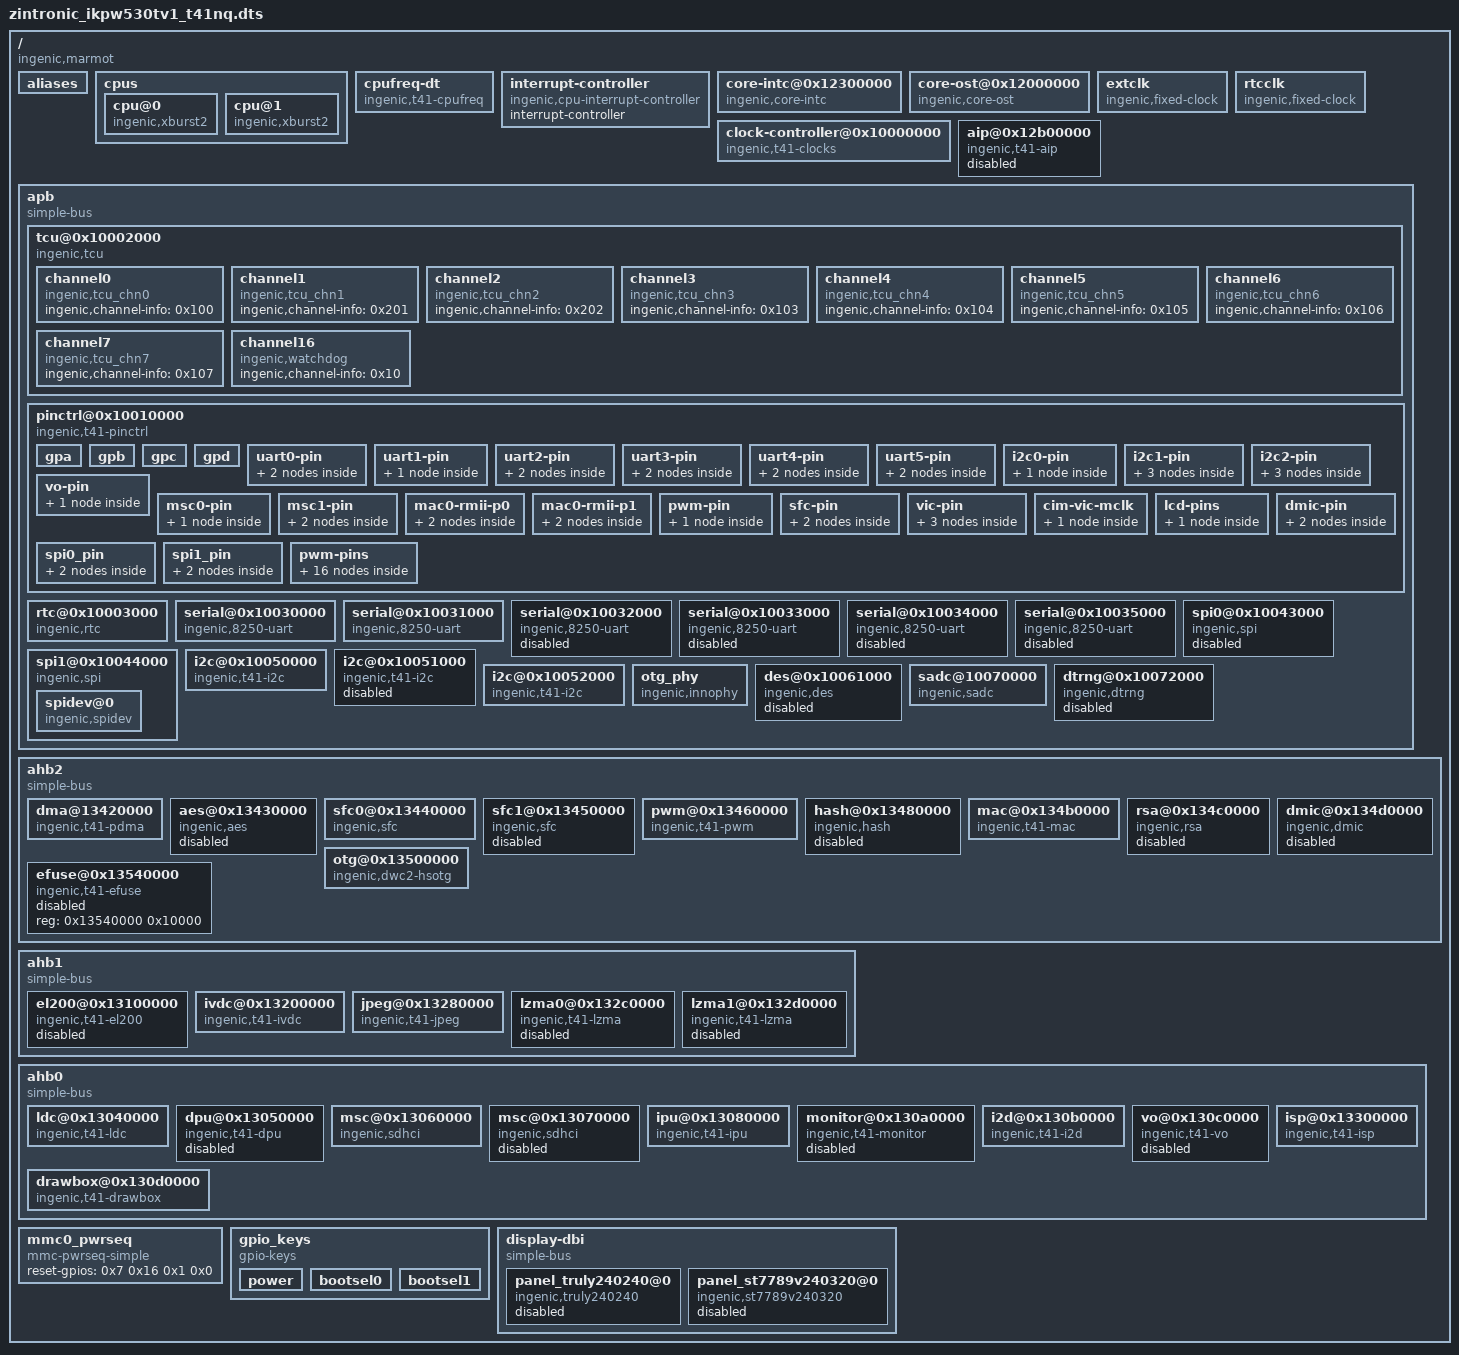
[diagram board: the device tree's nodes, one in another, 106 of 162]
/dts-v1/;
// version: 17
// last_comp_version: 16
// boot_cpuid_phys: 0x0

/ {
    #address-cells = <0x1>;
    #size-cells = <0x1>;
    compatible = "ingenic,marmot", "ingenic,t41";
    aliases {
        i2c0 = "/apb/i2c@0x10050000";
        i2c1 = "/apb/i2c@0x10051000";
        i2c2 = "/apb/i2c@0x10052000";
        vo = "/ahb0/vo@0x130c0000";
        uart0 = "/apb/serial@0x10030000";
        uart1 = "/apb/serial@0x10031000";
        uart2 = "/apb/serial@0x10032000";
        uart3 = "/apb/serial@0x10033000";
        uart4 = "/apb/serial@0x10034000";
        uart5 = "/apb/serial@0x10035000";
        msc0 = "/ahb0/msc@0x13060000";
        msc1 = "/ahb0/msc@0x13070000";
        mac0 = "/ahb2/mac@0x134b0000";
        spi0 = "/apb/spi0@0x10043000";
        spi1 = "/apb/spi1@0x10044000";
        sfc0 = "/ahb2/sfc0@0x13440000";
        sfc1 = "/ahb2/sfc1@0x13450000";
    };
    cpus {
        #address-cells = <0x1>;
        #size-cells = <0x0>;
        cpu@0 {
            device_type = "cpu";
            compatible = "ingenic,xburst2";
            reg = <0x0>;
            clock-frequency = <0x2FAF0800>;
        };
        cpu@1 {
            device_type = "cpu";
            compatible = "ingenic,xburst2";
            reg = <0x1>;
            clock-frequency = <0x2FAF0800>;
        };
    };
    cpufreq-dt {
        compatible = "ingenic,t41-cpufreq";
        status = "okay";
        operating-points = <0x124F80 0xDBBA0 0x10D880 0xDBBA0 0xF6180 0xDBBA0 0xDEA80 0xDBBA0 0xD9878 0xDBBA0 0xB71B0 0xDBBA0 0x927C0 0xDBBA0 0x7A120 0xDBBA0 0x61A80 0xDBBA0 0x5B8D8 0xDBBA0 0x493E0 0xDBBA0 0x30D40 0xDBBA0>;
    };
    interrupt-controller {
        #address-cells = <0x0>;
        #interrupt-cells = <0x1>;
        interrupt-controller;
        compatible = "ingenic,cpu-interrupt-controller";
        linux,phandle = <0x1>;
        phandle = <0x1>;
    };
    core-intc@0x12300000 {
        compatible = "ingenic,core-intc";
        reg = <0x12300000 0x1000>;
        interrupt-controller;
        #interrupt-cells = <0x1>;
        cpu-intc-map = <0x0 0x0 0x1 0x100 0x2 0x200 0x3 0x300>;
        interrupt-parent = <0x1>;
        interrupts = <0x2>;
        interrupt-names = "intc";
        linux,phandle = <0x4>;
        phandle = <0x4>;
    };
    core-ost@0x12000000 {
        compatible = "ingenic,core-ost";
        reg = <0x12000000 0x10000 0x12100000 0x10000>;
        interrupt-parent = <0x1>;
        interrupt-names = "sys_ost";
        interrupts = <0x4>;
        cpu-ost-map = <0x0 0x0 0x1 0x100>;
    };
    extclk {
        compatible = "ingenic,fixed-clock";
        clock-output-names = "ext";
        #clock-cells = <0x0>;
        clock-frequency = <0x16E3600>;
        linux,phandle = <0x2>;
        phandle = <0x2>;
    };
    rtcclk {
        compatible = "ingenic,fixed-clock";
        clock-output-names = "rtc_ext";
        #clock-cells = <0x0>;
        clock-frequency = <0x8000>;
        linux,phandle = <0x3>;
        phandle = <0x3>;
    };
    clock-controller@0x10000000 {
        compatible = "ingenic,t41-clocks";
        reg = <0x10000000 0x100>;
        clocks = <0x2 0x3>;
        clock-names = "ext", "rtc_ext";
        #clock-cells = <0x1>;
        little-endian;
    };
    aip@0x12b00000 {
        compatible = "ingenic,t41-aip";
        reg = <0x12B00000 0x10000>;
        interrupt-parent = <0x4>;
        interrupts = <0x28 0x27 0x26>;
        status = "disabled";
    };
    apb {
        compatible = "simple-bus";
        #address-cells = <0x1>;
        #size-cells = <0x1>;
        ranges;
        tcu@0x10002000 {
            compatible = "ingenic,tcu";
            reg = <0x10002000 0x200>;
            interrupt-parent = <0x4>;
            interrupt-names = "tcu_int0";
            interrupts = <0x1B>;
            interrupt-controller;
            status = "okay";
            channel0 {
                compatible = "ingenic,tcu_chn0";
                ingenic,channel-info = <0x100>;
            };
            channel1 {
                compatible = "ingenic,tcu_chn1";
                ingenic,channel-info = <0x201>;
            };
            channel2 {
                compatible = "ingenic,tcu_chn2";
                ingenic,channel-info = <0x202>;
            };
            channel3 {
                compatible = "ingenic,tcu_chn3";
                ingenic,channel-info = <0x103>;
            };
            channel4 {
                compatible = "ingenic,tcu_chn4";
                ingenic,channel-info = <0x104>;
            };
            channel5 {
                compatible = "ingenic,tcu_chn5";
                ingenic,channel-info = <0x105>;
            };
            channel6 {
                compatible = "ingenic,tcu_chn6";
                ingenic,channel-info = <0x106>;
            };
            channel7 {
                compatible = "ingenic,tcu_chn7";
                ingenic,channel-info = <0x107>;
            };
            channel16 {
                compatible = "ingenic,watchdog";
                ingenic,channel-info = <0x10>;
            };
        };
        pinctrl@0x10010000 {
            compatible = "ingenic,t41-pinctrl";
            reg = <0x10010000 0x1000>;
            ingenic,num-chips = <0x4>;
            ingenic,regs-offset = <0x100>;
            gpa {
                gpio-controller;
                #gpio-cells = <0x3>;
                #ingenic,pincfg-cells = <0x3>;
                #ingenic,pinmux-cells = <0x2>;
                interrupts = <0x11>;
                interrupt-parent = <0x4>;
                interrupt-controller;
                #interrupt-cells = <0x3>;
                ingenic,num-gpios = <0x20>;
                ingenic,pull-gpios-low = <0x55555555>;
                ingenic,pull-gpios-high = <0x55555555>;
                linux,phandle = <0x8>;
                phandle = <0x8>;
            };
            gpb {
                gpio-controller;
                #gpio-cells = <0x3>;
                #ingenic,pincfg-cells = <0x3>;
                #ingenic,pinmux-cells = <0x2>;
                interrupts = <0x10>;
                interrupt-parent = <0x4>;
                interrupt-controller;
                #interrupt-cells = <0x3>;
                ingenic,num-gpios = <0x20>;
                ingenic,pull-gpios-low = <0x55555555>;
                ingenic,pull-gpios-high = <0x55555555>;
                linux,phandle = <0x5>;
                phandle = <0x5>;
            };
            gpc {
                gpio-controller;
                #gpio-cells = <0x3>;
                #ingenic,pincfg-cells = <0x3>;
                #ingenic,pinmux-cells = <0x2>;
                interrupts = <0xF>;
                interrupt-parent = <0x4>;
                interrupt-controller;
                #interrupt-cells = <0x3>;
                ingenic,num-gpios = <0x20>;
                ingenic,pull-gpios-low = <0x55555555>;
                ingenic,pull-gpios-high = <0x55555555>;
                linux,phandle = <0x6>;
                phandle = <0x6>;
            };
            gpd {
                gpio-controller;
                #gpio-cells = <0x3>;
                #ingenic,pincfg-cells = <0x3>;
                #ingenic,pinmux-cells = <0x2>;
                interrupts = <0xE>;
                interrupt-parent = <0x4>;
                interrupt-controller;
                #interrupt-cells = <0x3>;
                ingenic,num-gpios = <0x20>;
                ingenic,pull-gpios-low = <0x55555555>;
                ingenic,pull-gpios-high = <0x55555555>;
                linux,phandle = <0x7>;
                phandle = <0x7>;
            };
            uart0-pin {
                uart0-pb {
                    ingenic,pinmux = <0x5 0x13 0x13 0x5 0x16 0x16>;
                    ingenic,pinmux-funcsel = <0x0>;
                };
                uart0-pc {
                    ingenic,pinmux = <0x6 0x8 0x9>;
                    ingenic,pinmux-funcsel = <0x0>;
                    linux,phandle = <0x9>;
                    phandle = <0x9>;
                };
            };
            uart1-pin {
                uart1-pb {
                    ingenic,pinmux = <0x5 0x17 0x18>;
                    ingenic,pinmux-funcsel = <0x0>;
                    linux,phandle = <0xA>;
                    phandle = <0xA>;
                };
            };
            uart2-pin {
                uart2-pc {
                    ingenic,pinmux = <0x6 0xD 0xE 0x6 0x13 0x14>;
                    ingenic,pinmux-funcsel = <0x0>;
                };
                uart2-pd {
                    ingenic,pinmux = <0x7 0x9 0xC>;
                    ingenic,pinmux-funcsel = <0x1>;
                    linux,phandle = <0xB>;
                    phandle = <0xB>;
                };
            };
            uart3-pin {
                uart3-pb {
                    ingenic,pinmux = <0x5 0x19 0x1A>;
                    ingenic,pinmux-funcsel = <0x1>;
                    linux,phandle = <0xC>;
                    phandle = <0xC>;
                };
                uart3-pd {
                    ingenic,pinmux = <0x7 0x0 0x1>;
                    ingenic,pinmux-funcsel = <0x2>;
                };
            };
            uart4-pin {
                uart4-pb {
                    ingenic,pinmux = <0x5 0x1D 0x1E>;
                    ingenic,pinmux-funcsel = <0x1>;
                    linux,phandle = <0xD>;
                    phandle = <0xD>;
                };
                uart4-pd {
                    ingenic,pinmux = <0x7 0x2 0x3>;
                    ingenic,pinmux-funcsel = <0x2>;
                };
            };
            uart5-pin {
                uart5-pb {
                    ingenic,pinmux = <0x5 0x6 0x7>;
                    ingenic,pinmux-funcsel = <0x1>;
                };
                uart5-pd {
                    ingenic,pinmux = <0x7 0x4 0x5>;
                    ingenic,pinmux-funcsel = <0x2>;
                    linux,phandle = <0xE>;
                    phandle = <0xE>;
                };
            };
            i2c0-pin {
                i2c0-pa {
                    ingenic,pinmux = <0x8 0xC 0xD>;
                    ingenic,pinmux-funcsel = <0x1>;
                    linux,phandle = <0x12>;
                    phandle = <0x12>;
                };
            };
            i2c1-pin {
                i2c1-pb {
                    ingenic,pinmux = <0x5 0x19 0x1A>;
                    ingenic,pinmux-funcsel = <0x0>;
                    linux,phandle = <0x13>;
                    phandle = <0x13>;
                };
                i2c1-pc {
                    ingenic,pinmux = <0x6 0x13 0x14>;
                    ingenic,pinmux-funcsel = <0x1>;
                };
                i2c1-pd {
                    ingenic,pinmux = <0x7 0x6 0x7>;
                    ingenic,pinmux-funcsel = <0x2>;
                };
            };
            i2c2-pin {
                i2c2-pb_1 {
                    ingenic,pinmux = <0x5 0xA 0xB>;
                    ingenic,pinmux-funcsel = <0x2>;
                };
                i2c2-pb_2 {
                    ingenic,pinmux = <0x5 0x1B 0x1C>;
                    ingenic,pinmux-funcsel = <0x1>;
                };
                i2c2-pc {
                    ingenic,pinmux = <0x6 0x8 0x9>;
                    ingenic,pinmux-funcsel = <0x1>;
                    linux,phandle = <0x14>;
                    phandle = <0x14>;
                };
            };
            vo-pin {
                vo-pd {
                    ingenic,pinmux = <0x7 0x0 0x8>;
                    ingenic,pinmux-funcsel = <0x1>;
                    linux,phandle = <0x1D>;
                    phandle = <0x1D>;
                };
            };
            msc0-pin {
                msc0-pb {
                    ingenic,pinmux = <0x5 0x0 0x5>;
                    ingenic,pinmux-funcsel = <0x0>;
                    linux,phandle = <0x1B>;
                    phandle = <0x1B>;
                };
            };
            msc1-pin {
                msc1-pb {
                    ingenic,pinmux = <0x5 0x11 0x16>;
                    ingenic,pinmux-funcsel = <0x1>;
                };
                msc1-pc {
                    ingenic,pinmux = <0x6 0x2 0x7>;
                    ingenic,pinmux-funcsel = <0x0>;
                    linux,phandle = <0x1C>;
                    phandle = <0x1C>;
                };
            };
            mac0-rmii-p0 {
                mac0-rmii-normal {
                    ingenic,pinmux = <0x5 0xF 0x10 0x5 0x9 0x9>;
                    ingenic,pinmux-funcsel = <0x0>;
                    linux,phandle = <0x17>;
                    phandle = <0x17>;
                };
                mac0-rmii-p0-rst {
                    ingenic,pinmux = <0x5 0xF 0x10 0x5 0x9 0x9>;
                    ingenic,pinmux-funcsel = <0x4>;
                    linux,phandle = <0x19>;
                    phandle = <0x19>;
                };
            };
            mac0-rmii-p1 {
                mac0-rmii-p1-normal {
                    ingenic,pinmux = <0x5 0x7 0x7 0x5 0xD 0xE 0x5 0x8 0x8 0x5 0xA 0xB 0x5 0x6 0x6>;
                    ingenic,pinmux-funcsel = <0x0>;
                    linux,phandle = <0x18>;
                    phandle = <0x18>;
                };
                mac0-rmii-p1-nomdio {
                    ingenic,pinmux = <0x5 0x7 0x7 0x5 0xD 0xE 0x5 0x8 0x8 0x5 0x6 0x6>;
                    ingenic,pinmux-funcsel = <0x0>;
                };
            };
            pwm-pin {
                pwm-pc {
                    ingenic,pinmux = <0x6 0xF 0x12>;
                    ingenic,pinmux-funcsel = <0x2>;
                };
            };
            sfc-pin {
                sfc0-pa {
                    ingenic,pinmux = <0x8 0x17 0x1C>;
                    ingenic,pinmux-funcsel = <0x1>;
                    linux,phandle = <0x15>;
                    phandle = <0x15>;
                };
                sfc1-pa {
                    ingenic,pinmux = <0x8 0x14 0x16 0x8 0x1D 0x1F>;
                    ingenic,pinmux-funcsel = <0x1>;
                    linux,phandle = <0x16>;
                    phandle = <0x16>;
                };
            };
            vic-pin {
                vic-pa-low-10bit {
                    ingenic,pinmux = <0x8 0x0 0x9 0x8 0xC 0xE>;
                    ingenic,pinmux-funcsel = <0x0>;
                };
                vic-pa-high-10bit {
                    ingenic,pinmux = <0x8 0x2 0xE>;
                    ingenic,pinmux-funcsel = <0x0>;
                };
                vic-pa-12bit {
                    ingenic,pinmux = <0x8 0x0 0xE>;
                    ingenic,pinmux-funcsel = <0x0>;
                };
            };
            cim-vic-mclk {
                cim0-vic-mclk-pa {
                    ingenic,pinmux = <0x8 0xF 0xF>;
                    ingenic,pinmux-funcsel = <0x1>;
                };
            };
            lcd-pins {
                smart-lcd-pd {
                    ingenic,pinmux = <0x7 0x0 0xC>;
                    ingenic,pinmux-funcsel = <0x0>;
                    linux,phandle = <0x1E>;
                    phandle = <0x1E>;
                };
            };
            dmic-pin {
                dmic-pb {
                    ingenic,pinmux = <0x5 0x1C 0x1E>;
                    ingenic,pinmux-funcsel = <0x0>;
                };
                dmic-pa {
                    ingenic,pinmux = <0x8 0xE 0xE 0x8 0x10 0x11>;
                    ingenic,pinmux-funcsel = <0x2>;
                };
            };
            spi0_pin {
                spi0-pa {
                    ingenic,pinmux = <0x8 0x6 0x9>;
                    ingenic,pinmux-funcsel = <0x2>;
                    linux,phandle = <0x10>;
                    phandle = <0x10>;
                };
                spi0-pc {
                    ingenic,pinmux = <0x6 0x2 0x5>;
                    ingenic,pinmux-funcsel = <0x1>;
                };
            };
            spi1_pin {
                spi1-pa {
                    ingenic,pinmux = <0x8 0x14 0x16 0x8 0x1D 0x1D>;
                    ingenic,pinmux-funcsel = <0x0>;
                    linux,phandle = <0x11>;
                    phandle = <0x11>;
                };
                spi1-pb {
                    ingenic,pinmux = <0x5 0x1B 0x1E>;
                    ingenic,pinmux-funcsel = <0x2>;
                };
            };
            pwm-pins {
                pwm0_pc {
                    ingenic,pinmux = <0x6 0xF 0xF>;
                    ingenic,pinmux-funcsel = <0x2>;
                };
                pwm0_pb {
                    ingenic,pinmux = <0x5 0x11 0x11>;
                    ingenic,pinmux-funcsel = <0x0>;
                };
                pwm1_pb {
                    ingenic,pinmux = <0x5 0x12 0x12>;
                    ingenic,pinmux-funcsel = <0x0>;
                };
                pwm1_pc {
                    ingenic,pinmux = <0x6 0x10 0x10>;
                    ingenic,pinmux-funcsel = <0x2>;
                };
                pwm2_pb {
                    ingenic,pinmux = <0x5 0x8 0x8>;
                    ingenic,pinmux-funcsel = <0x2>;
                };
                pwm2_pc {
                    ingenic,pinmux = <0x6 0x11 0x11>;
                    ingenic,pinmux-funcsel = <0x2>;
                };
                pwm3_pb {
                    ingenic,pinmux = <0x5 0x9 0x9>;
                    ingenic,pinmux-funcsel = <0x2>;
                };
                pwm3_pc {
                    ingenic,pinmux = <0x6 0x12 0x12>;
                    ingenic,pinmux-funcsel = <0x2>;
                };
                pwm4_pb {
                    ingenic,pinmux = <0x5 0xD 0xD>;
                    ingenic,pinmux-funcsel = <0x2>;
                };
                pwm4_pd {
                    ingenic,pinmux = <0x7 0x9 0x9>;
                    ingenic,pinmux-funcsel = <0x2>;
                };
                pwm5_pb {
                    ingenic,pinmux = <0x5 0xE 0xE>;
                    ingenic,pinmux-funcsel = <0x2>;
                };
                pwm5_pd {
                    ingenic,pinmux = <0x7 0xA 0xA>;
                    ingenic,pinmux-funcsel = <0x2>;
                };
                pwm6_pb {
                    ingenic,pinmux = <0x5 0xF 0xF>;
                    ingenic,pinmux-funcsel = <0x2>;
                };
                pwm6_pd {
                    ingenic,pinmux = <0x7 0xB 0xB>;
                    ingenic,pinmux-funcsel = <0x2>;
                };
                pwm7_pb {
                    ingenic,pinmux = <0x5 0x10 0x10>;
                    ingenic,pinmux-funcsel = <0x2>;
                };
                pwm7_pd {
                    ingenic,pinmux = <0x7 0xC 0xC>;
                    ingenic,pinmux-funcsel = <0x2>;
                };
            };
        };
        rtc@0x10003000 {
            compatible = "ingenic,rtc";
            reg = <0x10003000 0x1000>;
            interrupt-parent = <0x4>;
            interrupts = <0x3>;
            status = "okay";
        };
        serial@0x10030000 {
            compatible = "ingenic,8250-uart";
            reg = <0x10030000 0x1000>;
            reg-shift = <0x2>;
            interrupt-parent = <0x4>;
            interrupts = <0x33>;
            pinctrl-names = "default";
            pinctrl-0 = <0x9>;
            status = "okay";
        };
        serial@0x10031000 {
            compatible = "ingenic,8250-uart";
            reg = <0x10031000 0x1000>;
            reg-shift = <0x2>;
            interrupt-parent = <0x4>;
            interrupts = <0x32>;
            pinctrl-names = "default";
            pinctrl-0 = <0xA>;
            status = "okay";
        };
        serial@0x10032000 {
            compatible = "ingenic,8250-uart";
            reg = <0x10032000 0x1000>;
            reg-shift = <0x2>;
            interrupt-parent = <0x4>;
            interrupts = <0x31>;
            pinctrl-names = "default";
            pinctrl-0 = <0xB>;
            status = "disable";
        };
        serial@0x10033000 {
            compatible = "ingenic,8250-uart";
            reg = <0x10033000 0x1000>;
            reg-shift = <0x2>;
            interrupt-parent = <0x4>;
            interrupts = <0x30>;
            pinctrl-names = "default";
            pinctrl-0 = <0xC>;
            status = "disable";
        };
        serial@0x10034000 {
            compatible = "ingenic,8250-uart";
            reg = <0x10034000 0x1000>;
            reg-shift = <0x2>;
            interrupt-parent = <0x4>;
            interrupts = <0x39>;
            pinctrl-names = "default";
            pinctrl-0 = <0xD>;
            status = "disable";
        };
        serial@0x10035000 {
            compatible = "ingenic,8250-uart";
            reg = <0x10035000 0x1000>;
            reg-shift = <0x2>;
            interrupt-parent = <0x4>;
            interrupts = <0x38>;
            pinctrl-names = "default";
            pinctrl-0 = <0xE>;
            status = "disable";
        };
        spi0@0x10043000 {
            compatible = "ingenic,spi";
            reg = <0x10043000 0x1000>;
            interrupt-parent = <0x4>;
            interrupts = <0x9>;
            dmas = <0xF 0x16 0xF 0x17>;
            dma-names = "tx", "rx";
            #address-cells = <0x1>;
            #size-cells = <0x0>;
            status = "disable";
            pinctrl-names = "default";
            pinctrl-0 = <0x10>;
            spi-max-frequency = <0x2FAF080>;
            num-cs = <0x2>;
            cs-gpios = <0x0 0x0>;
            ingenic,chnl = <0x0>;
            ingenic,allow_cs_same = <0x1>;
            ingenic,bus_num = <0x0>;
            ingenic,has_dma_support = <0x1>;
        };
        spi1@0x10044000 {
            compatible = "ingenic,spi";
            reg = <0x10044000 0x1000>;
            interrupt-parent = <0x4>;
            interrupts = <0x8>;
            dmas = <0xF 0x18 0xF 0x19>;
            dma-names = "tx", "rx";
            #address-cells = <0x1>;
            #size-cells = <0x0>;
            status = "okay";
            pinctrl-names = "default";
            pinctrl-0 = <0x11>;
            spi-max-frequency = <0x2FAF080>;
            num-cs = <0x2>;
            cs-gpios = <0x0 0x0>;
            ingenic,chnl = <0x1>;
            ingenic,allow_cs_same = <0x1>;
            ingenic,bus_num = <0x1>;
            ingenic,has_dma_support = <0x1>;
            spidev@0 {
                compatible = "ingenic,spidev";
                reg = <0x0>;
                spi-max-frequency = <0x2FAF080>;
            };
        };
        i2c@0x10050000 {
            compatible = "ingenic,t41-i2c";
            reg = <0x10050000 0x1000>;
            interrupt-parent = <0x4>;
            interrupts = <0x3C>;
            #address-cells = <0x1>;
            #size-cells = <0x0>;
            status = "okay";
            pinctrl-0 = <0x12>;
            pinctrl-names = "default";
            clock-frequency = <0x61A80>;
        };
        i2c@0x10051000 {
            compatible = "ingenic,t41-i2c";
            reg = <0x10051000 0x1000>;
            interrupt-parent = <0x4>;
            interrupts = <0x3B>;
            #address-cells = <0x1>;
            #size-cells = <0x0>;
            status = "disable";
            pinctrl-0 = <0x13>;
            pinctrl-names = "default";
            clock-frequency = <0x61A80>;
        };
        i2c@0x10052000 {
            compatible = "ingenic,t41-i2c";
            reg = <0x10052000 0x1000>;
            interrupt-parent = <0x4>;
            interrupts = <0x3A>;
            #address-cells = <0x1>;
            #size-cells = <0x0>;
            status = "okay";
            pinctrl-0 = <0x14>;
            pinctrl-names = "default";
            clock-frequency = <0x61A80>;
        };
        otg_phy {
            compatible = "ingenic,innophy", "syscon";
            reg = <0x10000000 0x1000 0x10060000 0x1000>;
            dr_mode = "otg";
            ingenic,drvvbus-gpio = <0x0>;
            status = "okay";
            linux,phandle = <0x1A>;
            phandle = <0x1A>;
        };
        des@0x10061000 {
            compatible = "ingenic,des";
            reg = <0x10043000 0x1000>;
            dmas = <0xF 0x2E 0xF 0x2F>;
            dma-names = "tx", "rx";
            #address-cells = <0x1>;
            #size-cells = <0x0>;
            status = "disabled";
        };
        sadc@10070000 {
            compatible = "ingenic,sadc";
            reg = <0x10070000 0x1000>;
            interrupt-parent = <0x4>;
            interrupts = <0x12>;
            status = "okay";
        };
        dtrng@0x10072000 {
            compatible = "ingenic,dtrng";
            reg = <0x10072000 0x1000>;
            interrupt-parent = <0x4>;
            interrupts = <0x22>;
            status = "disable";
        };
    };
    ahb2 {
        compatible = "simple-bus";
        #address-cells = <0x1>;
        #size-cells = <0x1>;
        ranges;
        dma@13420000 {
            compatible = "ingenic,t41-pdma";
            reg = <0x13420000 0x10000>;
            interrupt-parent = <0x4>;
            interrupt-names = "pdma", "pdmam";
            interrupts = <0xA 0x3D>;
            #dma-channels = <0x20>;
            #dma-cells = <0x1>;
            ingenic,reserved-chs = <0x3>;
            status = "okay";
            linux,phandle = <0xF>;
            phandle = <0xF>;
        };
        aes@0x13430000 {
            compatible = "ingenic,aes";
            reg = <0x13430000 0x10000>;
            interrupt-parent = <0x4>;
            interrupts = <0x17>;
            status = "disabled";
        };
        sfc0@0x13440000 {
            compatible = "ingenic,sfc";
            reg = <0x13440000 0x10000>;
            interrupt-parent = <0x4>;
            interrupts = <0x7>;
            pinctrl-names = "default";
            pinctrl-0 = <0x15>;
            status = "okay";
            ingenic,sfc-max-frequency = <0x5F5E100>;
            ingenic,use_board_info = [00];
            ingenic,spiflash_param_offset = <0x0>;
            ingenic,spiflash_type = <0x0>;
        };
        sfc1@0x13450000 {
            compatible = "ingenic,sfc";
            reg = <0x13450000 0x10000>;
            interrupt-parent = <0x4>;
            interrupts = <0x13>;
            pinctrl-names = "default";
            pinctrl-0 = <0x16>;
            status = "disable";
            ingenic,sfc-max-frequency = <0x5F5E100>;
            ingenic,use_board_info = [00];
            ingenic,spiflash_param_offset = <0x0>;
            ingenic,spiflash_type = <0x1>;
        };
        pwm@0x13460000 {
            compatible = "ingenic,t41-pwm";
            reg = <0x13460000 0x1000>;
            interrupt-parent = <0x4>;
            interrupts = <0x3F>;
            #address-cells = <0x1>;
            #size-cells = <0x0>;
            status = "okay";
        };
        hash@0x13480000 {
            compatible = "ingenic,hash";
            reg = <0x13480000 0x10000>;
            interrupt-parent = <0x4>;
            interrupts = <0x16>;
            status = "disabled";
        };
        mac@0x134b0000 {
            compatible = "ingenic,t41-mac";
            reg = <0x134B0000 0x10000>;
            interrupt-parent = <0x4>;
            interrupts = <0x37>;
            status = "okay";
            ingenic,rst-ms = <0xA>;
            pinctrl-names = "default";
            pinctrl-0 = <0x17 0x18>;
            pinctrl-1 = <0x19 0x18>;
            ingenic,mac-mode = <0x4>;
            ingenic,mode-reg = <0xB00000E8>;
            ingenic,phy-clk-freq = <0x2faf080>;
        };
        rsa@0x134c0000 {
            compatible = "ingenic,rsa";
            reg = <0x134C0000 0x10000>;
            interrupt-parent = <0x4>;
            interrupts = <0x18>;
            status = "disabled";
        };
        dmic@0x134d0000 {
            compatible = "ingenic,dmic";
            reg = <0x134D0000 0x10000>;
            interrupt-parent = <0x4>;
            interrupts = <0x21>;
            status = "disabled";
        };
        otg@0x13500000 {
            compatible = "ingenic,dwc2-hsotg";
            reg = <0x13500000 0x40000>;
            interrupt-parent = <0x4>;
            interrupts = <0x15>;
            ingenic,usbphy = <0x1A>;
            status = "okay";
            g-use-dma;
            dr_mode = "otg";
        };
        efuse@0x13540000 {
            compatible = "ingenic,t41-efuse";
            reg = <0x13540000 0x10000>;
            status = "disabled";
        };
    };
    ahb1 {
        compatible = "simple-bus";
        #address-cells = <0x1>;
        #size-cells = <0x1>;
        ranges;
        el200@0x13100000 {
            compatible = "ingenic,t41-el200";
            reg = <0x13100000 0x100000>;
            interrupt-parent = <0x4>;
            interrupts = <0x3E>;
            status = "disable";
        };
        ivdc@0x13200000 {
            compatible = "ingenic,t41-ivdc";
            reg = <0x13200000 0x7FFFF>;
            interrupt-parent = <0x4>;
            interrupts = <0x0>;
            status = "okay";
        };
        jpeg@0x13280000 {
            compatible = "ingenic,t41-jpeg";
            reg = <0x13280000 0x3FFFF>;
            interrupt-parent = <0x4>;
            interrupts = <0x0>;
            status = "okay";
        };
        lzma0@0x132c0000 {
            compatible = "ingenic,t41-lzma";
            reg = <0x13C00000 0x10000>;
            interrupt-parent = <0x4>;
            interrupts = <0x4>;
            status = "disabled";
        };
        lzma1@0x132d0000 {
            compatible = "ingenic,t41-lzma";
            reg = <0x13D00000 0x10000>;
            interrupt-parent = <0x4>;
            interrupts = <0x4>;
            status = "disabled";
        };
    };
    ahb0 {
        compatible = "simple-bus";
        #address-cells = <0x1>;
        #size-cells = <0x1>;
        ranges;
        ldc@0x13040000 {
            compatible = "ingenic,t41-ldc";
            reg = <0x13040000 0x10000>;
            interrupt-parent = <0x4>;
            interrupts = <0x23>;
            status = "okay";
        };
        dpu@0x13050000 {
            compatible = "ingenic,t41-dpu";
            reg = <0x13050000 0x10000>;
            interrupt-parent = <0x4>;
            interrupts = <0x14>;
            status = "disable";
        };
        msc@0x13060000 {
            compatible = "ingenic,sdhci";
            reg = <0x13060000 0x10000>;
            status = "okay";
            interrupt-parent = <0x4>;
            interrupts = <0x25>;
            pinctrl-names = "default";
            pinctrl-0 = <0x1B>;
            cap-mmc-highspeed;
            max-frequency = <0x17D7840>;
            bus-width = <0x4>;
            voltage-ranges = <0x708 0xCE4>;
            cd-inverted;
            ingenic,wp-gpios = <0x0>;
            ingenic,cd-gpios = <0x5 0x1A 0x1 0x0>;
            ingenic,rst-gpios = <0x0>;
        };
        msc@0x13070000 {
            compatible = "ingenic,sdhci";
            reg = <0x13070000 0x10000>;
            status = "disable";
            interrupt-parent = <0x4>;
            interrupts = <0x24>;
            pinctrl-names = "default";
            pinctrl-0 = <0x1C>;
            cap-mmc-highspeed;
            max-frequency = <0x2FAF080>;
            bus-width = <0x4>;
            voltage-ranges = <0x708 0xCE4>;
            non-removable;
            ingenic,wp-gpios = <0x0>;
            ingenic,rst-gpios = <0x0>;
        };
        ipu@0x13080000 {
            compatible = "ingenic,t41-ipu";
            reg = <0x13080000 0x10000>;
            interrupt-parent = <0x4>;
            interrupts = <0x6>;
            status = "okay";
        };
        monitor@0x130a0000 {
            compatible = "ingenic,t41-monitor";
            reg = <0x130A0000 0x10000>;
            interrupt-parent = <0x4>;
            interrupts = <0x35>;
            status = "disabled";
        };
        i2d@0x130b0000 {
            compatible = "ingenic,t41-i2d";
            reg = <0x130B0000 0x10000>;
            interrupt-parent = <0x4>;
            interrupts = <0x2D>;
            status = "okay";
        };
        vo@0x130c0000 {
            compatible = "ingenic,t41-vo";
            reg = <0x130C0000 0x10000>;
            interrupt-parent = <0x4>;
            interrupts = <0x2B>;
            status = "disable";
            pinctrl-0 = <0x1D>;
            pinctrl-names = "default";
        };
        drawbox@0x130d0000 {
            compatible = "ingenic,t41-drawbox";
            reg = <0x130D0000 0x10000>;
            interrupt-parent = <0x4>;
            interrupts = <0x2A>;
            status = "okay";
        };
        isp@0x13300000 {
            compatible = "ingenic,t41-isp";
            reg = <0x13300000 0x100000>;
            interrupt-parent = <0x4>;
            interrupts = <0x1F>;
            status = "okay";
        };
    };
    mmc0_pwrseq {
        compatible = "mmc-pwrseq-simple";
        reset-gpios = <0x7 0x16 0x1 0x0>;
    };
    gpio_keys {
        compatible = "gpio-keys";
        power {
            label = "Power";
            linux,code = <0x74>;
            gpios = <0x6 0x8 0x1 0x0>;
            linux,input-type = <0x1>;
            gpio_key,wakeup = <0x1>;
            debounce-interval = <0x64>;
        };
        bootsel0 {
            label = "bootsel0";
            linux,code = <0x66>;
            gpios = <0x6 0x0 0x0 0x0>;
        };
        bootsel1 {
            label = "bootsel1";
            linux,code = <0x9E>;
            gpios = <0x6 0x1 0x0 0x0>;
        };
    };
    display-dbi {
        compatible = "simple-bus";
        #interrupt-cells = <0x1>;
        #address-cells = <0x1>;
        #size-cells = <0x1>;
        ranges;
        panel_truly240240@0 {
            compatible = "ingenic,truly240240";
            pinctrl-names = "default";
            pinctrl-0 = <0x1E>;
            ingenic,rst-gpio = <0x7 0x9 0x0 0x0>;
            ingenic,rd-gpio = <0x7 0xC 0x0 0x0>;
            ingenic,cs-gpio = <0x7 0xA 0x0 0x0>;
            status = "disable";
        };
        panel_st7789v240320@0 {
            compatible = "ingenic,st7789v240320";
            pinctrl-names = "default";
            pinctrl-0 = <0x1E>;
            ingenic,rst-gpio = <0x7 0x9 0x0 0x0>;
            ingenic,rd-gpio = <0x7 0xC 0x0 0x0>;
            ingenic,cs-gpio = <0x7 0xA 0x0 0x0>;
            ingenic,bl-gpio = <0x7 0x1B 0x0 0x0>;
            status = "disable";
        };
    };
};
